VERSION ""

NS_ :

BS_:

BU_: XXX

BO_ 179 DOOR_OPEN_FL: 8 XXX
 SG_ DOOR_OPEN_FL : 34|1@0+ (1,0) [0|1] "" XXX

BO_ 311 SEATBELT_DRIVER_UNLATCHED: 8 XXX
 SG_ SEATBELT_DRIVER_UNLATCHED : 60|5@0+ (1,0) [0|31] "" XXX

BO_ 792 TURN_SIGNALS: 8 XXX
 SG_ TURN_SIGNALS : 0|2@1+ (1,0) [0|3] "" XXX

BO_ 133 PRNDL: 8 XXX
 SG_ PRNDL : 5|14@0+ (1,0) [0|16383] "" XXX
 SG_ NEW_SIGNAL_1 : 40|2@1+ (1,0) [0|3] "" XXX

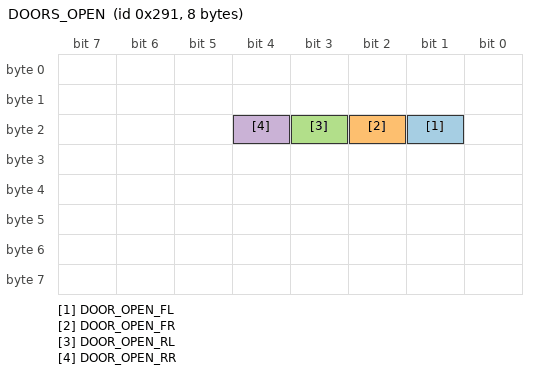
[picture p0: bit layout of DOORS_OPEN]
BO_ 657 DOORS_OPEN: 8 XXX
 SG_ DOOR_OPEN_FL : 17|1@0+ (1,0) [0|1] "" XXX
 SG_ DOOR_OPEN_FR : 18|1@1+ (1,0) [0|3] "" XXX
 SG_ DOOR_OPEN_RL : 19|1@0+ (1,0) [0|1] "" XXX
 SG_ DOOR_OPEN_RR : 20|1@0+ (1,0) [0|1] "" XXX

CM_ SG_ 792 TURN_SIGNALS "RIGHT IS 2 LEFT IS 1";
CM_ SG_ 133 NEW_SIGNAL_1 "2 WHEN NOT IN NEUTRAL 1 WHEN IN NEUTRAL";
